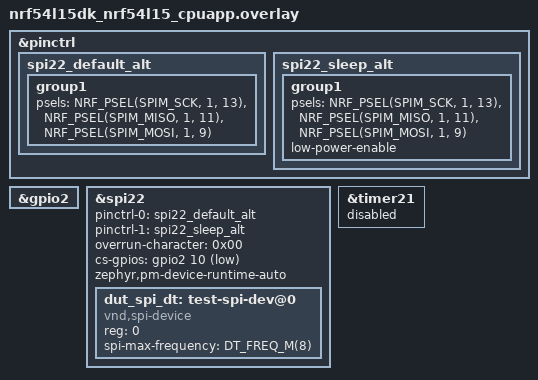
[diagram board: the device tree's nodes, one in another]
&pinctrl {
	spi22_default_alt: spi22_default_alt {
		group1 {
			psels = <NRF_PSEL(SPIM_SCK, 1, 13)>,
				<NRF_PSEL(SPIM_MISO, 1, 11)>,
				<NRF_PSEL(SPIM_MOSI, 1, 9)>;
		};
	};

	spi22_sleep_alt: spi22_sleep_alt {
		group1 {
			psels = <NRF_PSEL(SPIM_SCK, 1, 13)>,
				<NRF_PSEL(SPIM_MISO, 1, 11)>,
				<NRF_PSEL(SPIM_MOSI, 1, 9)>;
			low-power-enable;
		};
	};
};

&gpio2 {
	status = "okay";
};

dut_spim: &spi22 {
	status = "okay";
	pinctrl-0 = <&spi22_default_alt>;
	pinctrl-1 = <&spi22_sleep_alt>;
	pinctrl-names = "default", "sleep";
	overrun-character = <0x00>;
	cs-gpios = <&gpio2 10 GPIO_ACTIVE_LOW>;
	zephyr,pm-device-runtime-auto;
	dut_spi_dt: test-spi-dev@0 {
		compatible = "vnd,spi-device";
		reg = <0>;
		spi-max-frequency = <DT_FREQ_M(8)>;
	};
};

stopwatch: &timer21 {
	status = "reserved";
};
